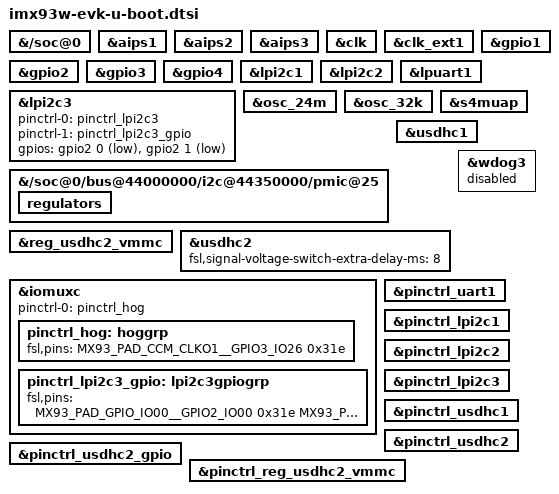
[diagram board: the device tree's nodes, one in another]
// SPDX-License-Identifier: GPL-2.0+
/*
 * Copyright 2026 NXP
 */

#include "imx93-u-boot.dtsi"

&{/soc@0} {
	bootph-all;
};

&aips1 {
	bootph-all;
};

&aips2 {
	bootph-pre-ram;
	bootph-some-ram;
};

&aips3 {
	bootph-pre-ram;
	bootph-some-ram;
};

&clk {
	bootph-all;
	/delete-property/ assigned-clocks;
	/delete-property/ assigned-clock-rates;
	/delete-property/ assigned-clock-parents;
};

&clk_ext1 {
	bootph-all;
};

&gpio1 {
	bootph-pre-ram;
	bootph-some-ram;
};

&gpio2 {
	bootph-pre-ram;
	bootph-some-ram;
};

&gpio3 {
	bootph-pre-ram;
	bootph-some-ram;
};

&gpio4 {
	bootph-pre-ram;
	bootph-some-ram;
};

&lpi2c1 {
	bootph-pre-ram;
};

&lpi2c2 {
	bootph-pre-ram;
};

&lpi2c3 {
	bootph-pre-ram;
	pinctrl-names = "default", "gpio";
	pinctrl-0 = <&pinctrl_lpi2c3>;
	pinctrl-1 = <&pinctrl_lpi2c3_gpio>;
	gpios = <&gpio2 0 GPIO_ACTIVE_LOW>,
		<&gpio2 1 GPIO_ACTIVE_LOW>;
};

&lpuart1 {
	bootph-pre-ram;
	bootph-some-ram;
};

&osc_24m {
	bootph-all;
};

&osc_32k {
	bootph-all;
};

&{/soc@0/bus@44000000/i2c@44350000/pmic@25} {
	bootph-pre-ram;
	bootph-some-ram;

	regulators {
		bootph-pre-ram;
		bootph-some-ram;
	};
};

&reg_usdhc2_vmmc {
	bootph-pre-ram;
};

&s4muap {
	bootph-pre-ram;
	bootph-some-ram;
};

&usdhc1 {
	bootph-pre-ram;
};

&usdhc2 {
	bootph-pre-ram;
	fsl,signal-voltage-switch-extra-delay-ms = <8>;
};

&wdog3 {
	status = "disabled";
};

&iomuxc {
	bootph-all;
	pinctrl-names = "default";
	pinctrl-0 = <&pinctrl_hog>;

	pinctrl_hog: hoggrp {
		bootph-all;
		fsl,pins = <
			MX93_PAD_CCM_CLKO1__GPIO3_IO26			0x31e
		>;
	};

	pinctrl_lpi2c3_gpio: lpi2c3gpiogrp {
		bootph-all;
		fsl,pins = <
			MX93_PAD_GPIO_IO00__GPIO2_IO00			0x31e
			MX93_PAD_GPIO_IO01__GPIO2_IO01			0x31e
		>;
	};
};

&pinctrl_uart1 {
	bootph-pre-ram;
	bootph-some-ram;
};

&pinctrl_lpi2c1 {
	bootph-pre-ram;
};

&pinctrl_lpi2c2 {
	bootph-pre-ram;
};

&pinctrl_lpi2c3 {
	bootph-pre-ram;
};

&pinctrl_usdhc1 {
	bootph-pre-ram;
};

&pinctrl_usdhc2 {
	bootph-pre-ram;
};

&pinctrl_usdhc2_gpio {
	bootph-pre-ram;
};

&pinctrl_reg_usdhc2_vmmc {
	bootph-pre-ram;
};
